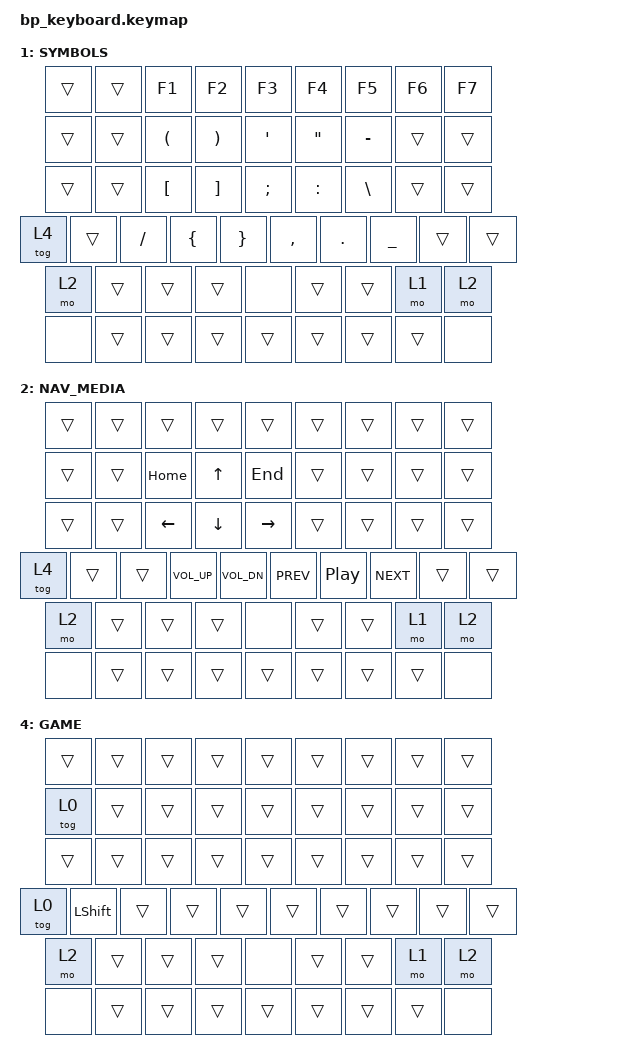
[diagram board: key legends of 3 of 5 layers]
/*
 * Copyright (c) 2026 BP Keyboard
 * SPDX-License-Identifier: MIT
 *
 * BP分体键盘 - 键位映射定义
 */

#include <dt-bindings/zmk/keys.h>
#include <dt-bindings/zmk/bt.h>
#include <dt-bindings/zmk/outputs.h>

/ {
    keymap {
        compatible = "zmk,keymap";

        default_layer {
            label = "BASE";

            // 左键盘 - 基础层
            // ROW0: Esc, `~, 1, 2, 3, 4, 5, 6, 7
            // ROW1: BSPC, Tab, Q, (无), W, E, R, T, Y
            // ROW2: Enter, Caps, A, (无), S, D, F, G, H
            // ROW3: TG5, Shift, \, Z, X, C, V, B, N
            // ROW4: MO2, Ctrl, Win, Alt, (无), Space, Space, MO1, MO2
            // ROW5: (无), F1, F2, F3, F4, F5, F6, F7, (无)

            bindings = <
                &kp ESC &kp GRAVE &kp N1 &kp N2 &kp N3 &kp N4 &kp N5 &kp N6 &kp N7
                &kp BSPC &kp TAB &kp Q &none &kp W &kp E &kp R &kp T &kp Y
                &kp RET &kp CAPS &kp A &none &kp S &kp D &kp F &kp G &kp H
                &tog 4 &kp LSHFT &kp BSLH &kp Z &kp X &kp C &kp V &kp B &kp N
                &mo 2 &kp LCTRL &kp LGUI &kp LALT &none &kp SPACE &kp SPACE &mo 1 &mo 2
                &none &kp F1 &kp F2 &kp F3 &kp F4 &kp F5 &kp F6 &kp F7 &none
            >;

            sensor-bindings = <&inc_kp &dec_kp>;
        };

        sym_layer {
            label = "SYMBOLS";

            // Layer 1: 符号/数字层
            bindings = <
                &trans &trans &kp F1 &kp F2 &kp F3 &kp F4 &kp F5 &kp F6 &kp F7
                &trans &trans &kp LPAR &kp RPAR &kp SQT &kp DQT &kp MINUS &trans &trans
                &trans &trans &kp LBKT &kp RBKT &kp SEMI &kp COLON &kp BSLH &trans &trans
                &tog 4 &trans &kp FSLH &kp LBRC &kp RBRC &kp COMMA &kp DOT &kp UNDER &trans &trans
                &mo 2 &trans &trans &trans &none &trans &trans &mo 1 &mo 2
                &none &trans &trans &trans &trans &trans &trans &trans &none
            >;

            sensor-bindings = <&inc_kp &dec_kp>;
        };

        nav_layer {
            label = "NAV_MEDIA";

            // Layer 2: 导航/媒体层
            bindings = <
                &trans &trans &trans &trans &trans &trans &trans &trans &trans
                &trans &trans &kp HOME &kp UP &kp END &trans &trans &trans &trans
                &trans &trans &kp LEFT &kp DOWN &kp RIGHT &trans &trans &trans &trans
                &tog 4 &trans &trans &kp C_VOL_UP &kp C_VOL_DN &kp C_PREV &kp C_PP &kp C_NEXT &trans &trans
                &mo 2 &trans &trans &trans &none &trans &trans &mo 1 &mo 2
                &none &trans &trans &trans &trans &trans &trans &trans &none
            >;

            sensor-bindings = <&inc_kp &dec_kp>;
        };

        sys_layer {
            label = "SYSMGR";

            // Layer 3: 系统管理层
            bindings = <
                &trans &trans &trans &trans &trans &trans &trans &trans &trans
                &studio_unlock &trans &bt BT_PRV &bt BT_NXT &trans &trans &trans &bt BT_CLR &trans
                &trans &trans &bt BT_SEL 0 &bt BT_SEL 1 &bt BT_SEL 2 &trans &trans &trans &trans
                &tog 4 &trans &out OUT_TOG &bt BT_SEL 3 &bt BT_SEL 4 &trans &trans &trans &trans
                &mo 2 &trans &trans &trans &none &trans &trans &mo 1 &mo 2
                &none &trans &trans &trans &trans &trans &trans &trans &none
            >;

            sensor-bindings = <&inc_kp &dec_kp>;
        };

        game_layer {
            label = "GAME";

            // Layer 4: 游戏模式层
            bindings = <
                &trans &trans &trans &trans &trans &trans &trans &trans &trans
                &tog 0 &trans &trans &trans &trans &trans &trans &trans &trans
                &trans &trans &trans &trans &trans &trans &trans &trans &trans
                &tog 0 &kp LSHFT &trans &trans &trans &trans &trans &trans &trans &trans
                &mo 2 &trans &trans &trans &none &trans &trans &mo 1 &mo 2
                &none &trans &trans &trans &trans &trans &trans &trans &none
            >;

            sensor-bindings = <&inc_kp &dec_kp>;
        };
    };
};
